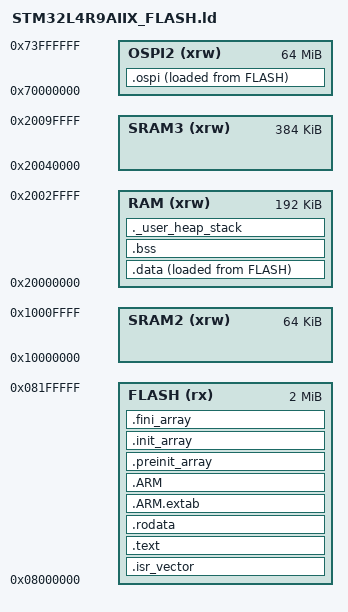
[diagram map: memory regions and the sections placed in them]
/*
******************************************************************************
**
** @file        : LinkerScript.ld
**
** @author      : Auto-generated by STM32CubeIDE
**
**  Abstract    : Linker script for STM32L4R9I-EVAL Board embedding STM32L4R9AIIx Device from stm32l4plus series
**                      2048Kbytes ROM
**                      192Kbytes RAM
**                      64Kbytes SRAM2
**                      384Kbytes SRAM3
**
**                Set heap size, stack size and stack location according
**                to application requirements.
**
**                Set memory bank area and size if external memory is used
**
**  Target      : STMicroelectronics STM32
**
**  Distribution: The file is distributed as is, without any warranty
**                of any kind.
**
******************************************************************************
** @attention
**
** Copyright (c) 2022 STMicroelectronics.
** All rights reserved.
**
** This software is licensed under terms that can be found in the LICENSE file
** in the root directory of this software component.
** If no LICENSE file comes with this software, it is provided AS-IS.
**
******************************************************************************
*/

/* Entry Point */
ENTRY(Reset_Handler)

/* Highest address of the user mode stack */
_estack = ORIGIN(RAM) + LENGTH(RAM);    /* end of RAM */
/* Generate a link error if heap and stack don't fit into RAM */
_Min_Heap_Size = 0x200;      /* required amount of heap  */
_Min_Stack_Size = 0x400; /* required amount of stack */

/* Specify the memory areas */
MEMORY
{
RAM (xrw)       : ORIGIN = 0x20000000, LENGTH = 192K
FLASH (rx)      : ORIGIN = 0x8000000, LENGTH = 2048K
OSPI2 (xrw)     : ORIGIN = 0x70000000, LENGTH = 65536K
SRAM3 (xrw)     : ORIGIN = 0x20040000, LENGTH = 384K
SRAM2 (xrw)     : ORIGIN = 0x10000000, LENGTH = 64K

}

/* Define output sections */
SECTIONS
{
  /* The startup code goes first into FLASH */
  .isr_vector :
  {
    . = ALIGN(8);
    KEEP(*(.isr_vector)) /* Startup code */
    . = ALIGN(8);
  } >FLASH

  /* The program code and other data goes into FLASH */
  .text :
  {
    . = ALIGN(8);
    *(.text)           /* .text sections (code) */
    *(.text*)          /* .text* sections (code) */
    *(.glue_7)         /* glue arm to thumb code */
    *(.glue_7t)        /* glue thumb to arm code */
    *(.eh_frame)

    KEEP (*(.init))
    KEEP (*(.fini))

    . = ALIGN(8);
    _etext = .;        /* define a global symbols at end of code */
  } >FLASH

  /* Constant data goes into FLASH */
  .rodata :
  {
    . = ALIGN(8);
    *(.rodata)         /* .rodata sections (constants, strings, etc.) */
    *(.rodata*)        /* .rodata* sections (constants, strings, etc.) */
    . = ALIGN(8);
  } >FLASH

  .ARM.extab   : 
  { 
  . = ALIGN(8);
  *(.ARM.extab* .gnu.linkonce.armextab.*)
  . = ALIGN(8);
  } >FLASH
  .ARM : {
	. = ALIGN(8);
    __exidx_start = .;
    *(.ARM.exidx*)
    __exidx_end = .;
	. = ALIGN(8);
  } >FLASH

_ospi_nor_init_base = LOADADDR(.ospi);
_ospi_nor_init_length = SIZEOF(.ospi);
   .ospi :
  {
    . = ALIGN(4);
    _ospi_start = .;        /* create a global symbol at qspi start */
    *(.ospi)         /* .ospi sections */
    *(.ospi*)        /* .ospi* sections */
    . = ALIGN(4);
    _ospi_end = .;         /* define a global symbols at end of qspi */
    
  } >OSPI2 AT> FLASH

  .preinit_array     :
  {
	. = ALIGN(8);
    PROVIDE_HIDDEN (__preinit_array_start = .);
    KEEP (*(.preinit_array*))
    PROVIDE_HIDDEN (__preinit_array_end = .);
	. = ALIGN(8);
  } >FLASH
  
  .init_array :
  {
	. = ALIGN(8);
    PROVIDE_HIDDEN (__init_array_start = .);
    KEEP (*(SORT(.init_array.*)))
    KEEP (*(.init_array*))
    PROVIDE_HIDDEN (__init_array_end = .);
	. = ALIGN(8);
  } >FLASH
  .fini_array :
  {
	. = ALIGN(8);
    PROVIDE_HIDDEN (__fini_array_start = .);
    KEEP (*(SORT(.fini_array.*)))
    KEEP (*(.fini_array*))
    PROVIDE_HIDDEN (__fini_array_end = .);
	. = ALIGN(8);
  } >FLASH

  /* used by the startup to initialize data */
  _sidata = LOADADDR(.data);

  /* Initialized data sections goes into RAM, load LMA copy after code */
  .data : 
  {
    . = ALIGN(8);
    _sdata = .;        /* create a global symbol at data start */
    *(.data)           /* .data sections */
    *(.data*)          /* .data* sections */

    . = ALIGN(8);
    _edata = .;        /* define a global symbol at data end */
  } >RAM AT> FLASH


  
  /* Uninitialized data section */
  . = ALIGN(4);
  .bss :
  {
    /* This is used by the startup in order to initialize the .bss secion */
    _sbss = .;         /* define a global symbol at bss start */
    __bss_start__ = _sbss;
    *(.bss)
    *(.bss*)
    *(COMMON)

    . = ALIGN(4);
    _ebss = .;         /* define a global symbol at bss end */
    __bss_end__ = _ebss;
  } >RAM

  /* User_heap_stack section, used to check that there is enough RAM left */
  ._user_heap_stack :
  {
    . = ALIGN(8);
    PROVIDE ( end = . );
    PROVIDE ( _end = . );
    . = . + _Min_Heap_Size;
    . = . + _Min_Stack_Size;
    . = ALIGN(8);
  } >RAM

  

  /* Remove information from the standard libraries */
  /DISCARD/ :
  {
    libc.a ( * )
    libm.a ( * )
    libgcc.a ( * )
  }

  .ARM.attributes 0 : { *(.ARM.attributes) }
}


